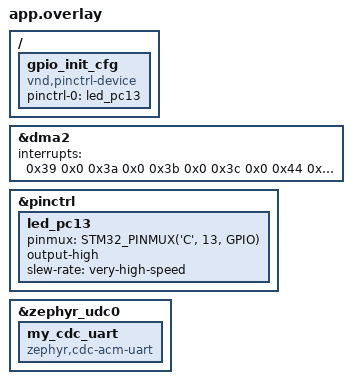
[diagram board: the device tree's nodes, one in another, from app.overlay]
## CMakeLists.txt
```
# SPDX-License-Identifier: Apache-2.0

cmake_minimum_required(VERSION 3.20.0)
find_package(Zephyr REQUIRED HINTS $ENV{ZEPHYR_BASE})
project(blinky)

target_sources(app PRIVATE src/main.c src/adc.c src/uart.c src/service.c)

set(ELF_FILE ${PROJECT_BINARY_DIR}/zephyr/zephyr.elf)

add_custom_target(dap-flash
    COMMAND openocd -f interface/cmsis-dap.cfg -f target/stm32f4x.cfg -c "program ${ELF_FILE} verify reset exit"
    DEPENDS ${ELF_FILE}
    COMMENT "正在透過 dap-link 燒錄 ${ELF_FILE} ..."
    USES_TERMINAL
)
```

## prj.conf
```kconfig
CONFIG_GPIO=y
CONFIG_SHELL=y

CONFIG_ADC=y
CONFIG_ADC_STM32=y
CONFIG_ADC_STM32_DMA=y
CONFIG_DMA=y
CONFIG_DMA_STM32=y
CONFIG_COUNTER=y
CONFIG_COUNTER_TIMER_STM32=y

CONFIG_USB_DEVICE_STACK=y
# CONFIG_USB_DEVICE_VID=<已分配的 VID>
# CONFIG_USB_DEVICE_PID=<產品專用的 PID>
CONFIG_USB_DEVICE_PRODUCT="My Zephyr USB Device"
CONFIG_USB_CDC_ACM=y
CONFIG_USB_CDC_ACM_RINGBUF_SIZE=4096
CONFIG_UART_LINE_CTRL=y

# CONFIG_USE_STM32_HAL_ADC=y

# CONFIG_PM=y
# CONFIG_PM_DEVICE=y

CONFIG_LOG=y

CONFIG_DEBUG=y
```

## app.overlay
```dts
#include <zephyr/dt-bindings/pinctrl/stm32-pinctrl.h>

/ {
    gpio_init_cfg: gpio_init_cfg {
        compatible = "vnd,pinctrl-device";
        pinctrl-0 = <&led_pc13>;
        pinctrl-names = "default";
        status = "okay";
    };
};

&dma2 {
    // interrupts = < 0x38 0x0 0x39 0x0 0x3a 0x0 0x3b 0x0 0x3c 0x0 0x44 0x0 0x45 0x0 0x46 0x0 >;

    // Remove the interrupt for DMA2 Stream 0 (0x38 ADC1 DMA) for custom handling in adc.c
    interrupts = < 0x39 0x0 0x3a 0x0 0x3b 0x0 0x3c 0x0 0x44 0x0 0x45 0x0 0x46 0x0 >;
    status = "okay";
};

&pinctrl {
    /omit-if-no-ref/ led_pc13: led_pc13 {
		pinmux = <STM32_PINMUX('C', 13, GPIO)>;
        // bias-disable;
        // drive-push-pull;
        output-high;
        slew-rate = "very-high-speed";
	};
};

&zephyr_udc0 {
    status = "okay";

    /* 建立獨立的虛擬序列埠節點 */
    my_cdc_uart: my_cdc_uart {
        compatible = "zephyr,cdc-acm-uart";
    };
};
```

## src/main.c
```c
/*
 * Copyright (c) 2016 Intel Corporation
 *
 * SPDX-License-Identifier: Apache-2.0
 */

#include <errno.h>
#include <zephyr/kernel.h>

#include "service.h"
#include "uart.h"

int main(void)
{
    int ret;

    ret = cdc_uart_init();
    if (ret != 0) {
        printk("CDC UART initialization failed: %d\n", ret);
        return ret;
    }

    ret = service_start();
    if (ret != 0) {
        printk("ADC service start failed: %d\n", ret);
        return ret;
    }

    return 0;
}



#include <zephyr/init.h>
#include <zephyr/drivers/pinctrl.h>

static int gpio_init(void) {

    printk("Config gpio table\n");

    PINCTRL_DT_DEFINE(DT_NODELABEL(gpio_init_cfg));
    const struct pinctrl_dev_config *gpio_init_pcfg =
        PINCTRL_DT_DEV_CONFIG_GET(DT_NODELABEL(gpio_init_cfg));
    int ret = pinctrl_apply_state(gpio_init_pcfg, PINCTRL_STATE_DEFAULT);
    if (ret < 0) {
        printk("Failed to apply pinctrl state: %d\n", ret);
        return ret;
    }

    return 0;
}

SYS_INIT(gpio_init, APPLICATION, 0);
```

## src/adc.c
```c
#include <soc.h>
#include <stm32f4xx.h>
#include <zephyr/arch/cpu.h>
#include <zephyr/irq.h>
#include <zephyr/kernel.h>
#include <zephyr/init.h>

#include "adc.h"

/* 宣告 DMA 雙暫存器/循環緩衝區 */
static uint16_t adc_dma_buffer[DMA_BUF_SAMPLES] __aligned(4);

/* Queue for pointer + length pair */
K_MSGQ_DEFINE(adc_msgq, sizeof(struct adc_dma_chunk), 4, 4);

/**
 * @brief DMA2 Stream 0 中斷服務程式 (ISR)
 * 當 DMA 搬移滿一半 (1000 samples) 或全滿 (2000 samples) 時觸發
 */
static void dma2_stream0_isr(const void *arg) {
    ARG_UNUSED(arg);

    struct adc_dma_chunk msg = {0};

    if (DMA2->LISR & DMA_LISR_HTIF0) {
        DMA2->LIFCR = DMA_LIFCR_CHTIF0;

        msg.buffer = adc_dma_buffer;
        msg.length = DMA_HALF_SAMPLES;
        k_msgq_put(&adc_msgq, &msg, K_NO_WAIT);
    }

    if (DMA2->LISR & DMA_LISR_TCIF0) {
        DMA2->LIFCR = DMA_LIFCR_CTCIF0;

        msg.buffer = &adc_dma_buffer[DMA_HALF_SAMPLES];
        msg.length = DMA_HALF_SAMPLES;
        k_msgq_put(&adc_msgq, &msg, K_NO_WAIT);
    }
}

/**
 * @brief TIM3 中斷服務程式 (ISR)
 * 1kHz 頻率觸發
 */
static void tim3_isr(const void *arg) {
    ARG_UNUSED(arg);

    if (TIM3->SR & TIM_SR_UIF) {
        TIM3->SR = ~TIM_SR_UIF;
    }
}

/**
 * @brief 初始化 ADC1, TIM3, DMA2 及 GPIOA (PA0)
 */
static int adc_custom_init(void) {
    /* =========================================================================
     * 1. 致能週邊時脈 (RCC)
     * =========================================================================
     */
    RCC->AHB1ENR |= RCC_AHB1ENR_GPIOAEN; // 致能 GPIOA 時脈 [25]
    RCC->AHB1ENR |= RCC_AHB1ENR_DMA2EN;  // 致能 DMA2 時脈 [25]
    RCC->APB2ENR |= RCC_APB2ENR_ADC1EN;  // 致能 ADC1 時脈 [26]
    RCC->APB1ENR |= RCC_APB1ENR_TIM3EN;  // 致能 TIM3 時脈 [27]

    /* =========================================================================
     * 2. 設定 PA0 為模擬輸入模式 (Analog Mode)
     * =========================================================================
     */
    GPIOA->MODER |=
        GPIO_MODER_MODE0_0 | GPIO_MODER_MODE0_1; // MODER0 = 11 (Analog) [28]
    GPIOA->PUPDR &= ~(GPIO_PUPDR_PUPD0_0 |
                      GPIO_PUPDR_PUPD0_1); // PUPDR0 = 00 (No pull) [29]

    /* =========================================================================
     * 3. 設定 DMA2 Stream 0 Channel 0 (對應 ADC1)
     * =========================================================================
     */
    DMA2_Stream0->CR &= ~DMA_SxCR_EN;
    while (DMA2_Stream0->CR & DMA_SxCR_EN)
        ; // 等待 Stream 完全關閉 [30]

    DMA2_Stream0->PAR =
        (uint32_t) & (ADC1->DR); // 週邊目標位址：ADC1 Data Register [31]
    DMA2_Stream0->M0AR =
        (uint32_t)adc_dma_buffer; // 記憶體目標位址：RAM Buffer [32]
    DMA2_Stream0->NDTR = DMA_BUF_SAMPLES; // 傳輸總筆數：2000 筆 Half-Word [33]

    DMA2_Stream0->CR =
        (0 << DMA_SxCR_CHSEL_Pos) | // Channel 0 [14, 34]
        DMA_SxCR_PL_1 |             // 優先級：High [35, 36]
        DMA_SxCR_MSIZE_0 | // 記憶體資料寬度：16-bit (Half-word) [18, 36]
        DMA_SxCR_PSIZE_0 | // 週邊資料寬度：16-bit (Half-word) [18, 36]
        DMA_SxCR_MINC |    // 記憶體地址自動遞增 [37, 38]
        DMA_SxCR_CIRC |    // 啟用循環模式 (Circular Mode) [39, 40]
        DMA_SxCR_HTIE |    // 滿一半 (Half Transfer) 中斷致能 [20, 21]
        DMA_SxCR_TCIE;     // 全滿 (Transfer Complete) 中斷致能 [20, 21]

    DMA2_Stream0->CR |= DMA_SxCR_EN; // 啟動 DMA Stream [20, 41]

    /* =========================================================================
     * 4. 設定 ADC1 (12-bit, 通道 0, 外部 TIM3 TRGO 觸發)
     * =========================================================================
     */
    ADC1_COMMON->CCR &= ~ADC_CCR_ADCPRE;
    ADC1_COMMON->CCR |=
        ADC_CCR_ADCPRE_0; // ADCCLK = PCLK2 / 4 = 96MHz / 4 = 24MHz [42]

    ADC1->CR1 = 0; // 12-bit 解析度，單次/掃描模式設為預設 [43]

    ADC1->CR2 =
        ADC_CR2_DMA | // 致能 ADC DMA [44]
        ADC_CR2_DDS | // 允許 DMA 在循環模式下持續發送請求 [44, 45]
        (0x8 << ADC_CR2_EXTSEL_Pos) | // EXTSEL = 1000b (TIM3 TRGO) [11, 12]
        (0x1 << ADC_CR2_EXTEN_Pos); // 觸發極性：上升沿 (Rising edge) [13]

    ADC1->SQR1 = 0; // 常規序列長度 L = 1 次轉換 [23]
    ADC1->SQR3 = 0; // 第 1 次轉換目標為 Channel 0 (PA0) [46]
    ADC1->SMPR2 |=
        (0x3 << ADC_SMPR2_SMP0_Pos); // Channel 0 採樣時間設為 56 週期 [47]

    ADC1->CR2 |= ADC_CR2_ADON; // 開啟 ADC 電源 [48, 49]

    /* =========================================================================
     * 5. 設定 TIM3 (產生 1kHz TRGO 訊號與 Update 中斷)
     * =========================================================================
     */
    TIM3->PSC = 95;  // Prescaler: 96MHz / (95 + 1) = 1MHz [5]
    TIM3->ARR = 999; // Period: 1MHz / (999 + 1) = 1kHz [6]

    TIM3->CR2 &= ~TIM_CR2_MMS;
    TIM3->CR2 |=
        (0x2 << TIM_CR2_MMS_Pos); // MMS = 010b (Update Event 作為 TRGO) [7, 8]
    // TIM3->DIER |= TIM_DIER_UIE;   // 啟用 Update 中斷 [50, 51]

    /* =========================================================================
     * 6. 在 Zephyr 系統中註冊與開啟 NVIC 中斷
     * =========================================================================
     */
    // 註冊 DMA2 Stream 0 中斷 (IRQ 56) [52]
    IRQ_CONNECT(DMA2_Stream0_IRQn, 1, dma2_stream0_isr, NULL, 0);
    irq_enable(DMA2_Stream0_IRQn);

    // 註冊 TIM3 中斷 (IRQ 29) [53]
    // IRQ_CONNECT(TIM3_IRQn, 2, tim3_isr, NULL, 0);
    // irq_enable(TIM3_IRQn);

    /* 啟動 TIM3 開始計數並輸出 TRGO 觸發 ADC */
    TIM3->CR1 |= TIM_CR1_CEN; // [ 54, 55 ]

    return 0;
}

SYS_INIT(adc_custom_init, APPLICATION, 0);
```

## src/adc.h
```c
#ifndef ADC_H
#define ADC_H

#include <stddef.h>
#include <stdint.h>
#include <zephyr/kernel.h>

/* Each DMA half contains 1000 samples, about one second at 1 kHz. */
#define DMA_BUF_SIZE_BYTES 4000U
#define DMA_BUF_SAMPLES (DMA_BUF_SIZE_BYTES / sizeof(uint16_t))
#define DMA_HALF_SAMPLES (DMA_BUF_SAMPLES / 2U)

struct adc_dma_chunk {
    uint16_t *buffer;
    size_t length;
};

extern struct k_msgq adc_msgq;

void adc_sample_init(void);
void adc_sample_start(void);
void adc_sample_stop(void);

#endif /* ADC_H */
```

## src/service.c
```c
#include <errno.h>
#include <stddef.h>
#include <stdint.h>
#include <string.h>

#include <zephyr/drivers/gpio.h>
#include <zephyr/kernel.h>
#include <zephyr/logging/log.h>

#include "adc.h"
#include "service.h"
#include "uart.h"

LOG_MODULE_REGISTER(service, LOG_LEVEL_INF);

#define PACKET_START_MAGIC "SERR"
#define PACKET_END_MAGIC   "IALL"
#define PACKET_HEADER_SIZE 7U
#define PACKET_TRAILER_SIZE 4U
#define SERVICE_STACK_SIZE 2048
#define SERVICE_PRIORITY 5

#define LED0_NODE DT_ALIAS(led0)

enum service_state {
    SERVICE_WAIT,
    SERVICE_SEND,
};

static const struct gpio_dt_spec led = GPIO_DT_SPEC_GET(LED0_NODE, gpios);
static K_THREAD_STACK_DEFINE(service_stack, SERVICE_STACK_SIZE);
static struct k_thread service_thread;
static uint8_t packet[PACKET_HEADER_SIZE +
                      (DMA_HALF_SAMPLES * sizeof(uint16_t)) +
                      PACKET_TRAILER_SIZE];
static bool service_started;

static void service_thread_fn(void *arg1, void *arg2, void *arg3)
{
    ARG_UNUSED(arg1);
    ARG_UNUSED(arg2);
    ARG_UNUSED(arg3);

    enum service_state state = SERVICE_WAIT;
    struct adc_dma_chunk msg;
    bool host_ready = false;

    while (true) {
        int ret = k_msgq_get(&adc_msgq, &msg, K_FOREVER);
        if (ret != 0) {
            LOG_ERR("ADC message queue receive failed: %d", ret);
            continue;
        }

        bool send_current_msg = false;
        switch (state) {
        case SERVICE_WAIT:
            host_ready = cdc_uart_host_ready();

            if (!host_ready) {
                LOG_INF("WAIT: dropping ADC data; host is not ready");
                break;
            }

            state = SERVICE_SEND;
            LOG_INF("WAIT -> SEND: host ready");
            send_current_msg = true;
            break;

        case SERVICE_SEND:
            host_ready = cdc_uart_host_ready();

            if (!host_ready) {
                LOG_WRN("SEND -> WAIT: host not ready");
                state = SERVICE_WAIT;
                break;
            }

            send_current_msg = true;
            break;
        }

        if (!send_current_msg) {
            continue;
        }

        if (msg.buffer == NULL || msg.length == 0U ||
            msg.length > DMA_HALF_SAMPLES || msg.length > UINT16_MAX) {
            LOG_ERR("Invalid ADC chunk: buffer=%p length=%zu",
                    msg.buffer, msg.length);
            continue;
        }

        memcpy(packet, PACKET_START_MAGIC, 4U);
        packet[4] = 1U;
        packet[5] = (uint8_t)(msg.length & 0xffU);
        packet[6] = (uint8_t)((msg.length >> 8) & 0xffU);
        memcpy(&packet[PACKET_HEADER_SIZE], msg.buffer,
               msg.length * sizeof(*msg.buffer));
        memcpy(&packet[PACKET_HEADER_SIZE +
                       (msg.length * sizeof(*msg.buffer))],
               PACKET_END_MAGIC, PACKET_TRAILER_SIZE);

        size_t packet_length = PACKET_HEADER_SIZE +
                               (msg.length * sizeof(*msg.buffer)) +
                               PACKET_TRAILER_SIZE;
        ret = send_adc_pack(packet, packet_length);
        if (ret != 0) {
            LOG_ERR("CDC packet send failed: %d; returning to WAIT", ret);
            host_ready = false;
            cdc_uart_clear_host_ready();
            state = SERVICE_WAIT;
            continue;
        }

        ret = gpio_pin_toggle_dt(&led);
        if (ret != 0) {
            LOG_ERR("LED toggle failed: %d", ret);
        }
    }
}

int service_start(void)
{
    int ret;

    if (service_started) {
        return -EALREADY;
    }

    if (!gpio_is_ready_dt(&led)) {
        return -ENODEV;
    }

    ret = gpio_pin_configure_dt(&led, GPIO_OUTPUT_INACTIVE);
    if (ret != 0) {
        LOG_ERR("LED configuration failed: %d", ret);
        return ret;
    }

    k_thread_create(&service_thread, service_stack,
                    K_THREAD_STACK_SIZEOF(service_stack),
                    service_thread_fn, NULL, NULL, NULL,
                    SERVICE_PRIORITY, 0, K_NO_WAIT);
    k_thread_name_set(&service_thread, "adc_service");
    service_started = true;
    return 0;
}
```

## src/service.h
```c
#ifndef SERVICE_H
#define SERVICE_H

int service_start(void);

#endif /* SERVICE_H */
```

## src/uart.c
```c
#include <errno.h>
#include <limits.h>
#include <stdbool.h>
#include <stddef.h>
#include <stdint.h>

#include <zephyr/device.h>
#include <zephyr/drivers/uart.h>
#include <zephyr/kernel.h>
#include <zephyr/sys/atomic.h>
#include <zephyr/usb/usb_device.h>

#include "uart.h"

#define HOST_READY_BYTE 0xA5U

static const struct device *const usb_uart_dev =
    DEVICE_DT_GET(DT_NODELABEL(my_cdc_uart));

static bool uart_initialized;
static atomic_t host_ready;

static void uart_rx_callback(const struct device *dev, void *user_data)
{
    ARG_UNUSED(user_data);

    if (!uart_irq_update(dev) || !uart_irq_rx_ready(dev)) {
        return;
    }

    uint8_t byte;
    while (uart_fifo_read(dev, &byte, 1) == 1) {
        if (byte == HOST_READY_BYTE) {
            atomic_set(&host_ready, 1);
        }
    }
}

int cdc_uart_init(void)
{
    int ret;

    if (!device_is_ready(usb_uart_dev)) {
        return -ENODEV;
    }

    ret = usb_enable(NULL);
    if (ret != 0) {
        return ret;
    }

    uart_irq_callback_set(usb_uart_dev, uart_rx_callback);
    uart_irq_rx_enable(usb_uart_dev);
    uart_initialized = true;
    return 0;
}

bool cdc_uart_host_ready(void)
{
    return atomic_get(&host_ready) != 0;
}

void cdc_uart_clear_host_ready(void)
{
    atomic_clear(&host_ready);
}

int send_adc_pack(const uint8_t *packet, size_t packet_length)
{
    int written;

    if (!uart_initialized) {
        return -EACCES;
    }
    if (packet == NULL || packet_length == 0U ||
        packet_length > CONFIG_USB_CDC_ACM_RINGBUF_SIZE ||
        packet_length > INT_MAX) {
        return -EINVAL;
    }

    written = uart_fifo_fill(usb_uart_dev, packet, (int)packet_length);
    if (written != (int)packet_length) {
        return written < 0 ? written : -ENOSPC;
    }

    return 0;
}
```

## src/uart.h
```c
#ifndef UART_H
#define UART_H

#include <stdbool.h>
#include <stddef.h>
#include <stdint.h>

int cdc_uart_init(void);
bool cdc_uart_host_ready(void);
void cdc_uart_clear_host_ready(void);
int send_adc_pack(const uint8_t *packet, size_t packet_length);

#endif /* UART_H */
```
